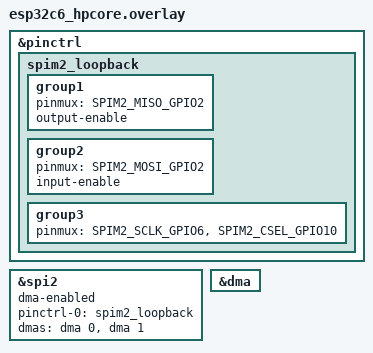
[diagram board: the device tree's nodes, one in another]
/*
 * Copyright (c) 2022 Kumar Gala <galak@kernel.org>
 *
 * SPDX-License-Identifier: Apache-2.0
 */

&pinctrl {
	spim2_loopback: spim2_loopback {
		group1 {
			pinmux = <SPIM2_MISO_GPIO2>;
			output-enable; /* Enable internal loopback */
		};

		group2 {
			pinmux = <SPIM2_MOSI_GPIO2>;
			input-enable; /* Enable internal loopback */
		};

		group3 {
			pinmux = <SPIM2_SCLK_GPIO6>,
				 <SPIM2_CSEL_GPIO10>;
		};
	};
};

spi_loopback: &spi2 {
	#address-cells = <1>;
	#size-cells = <0>;
	dma-enabled;
	pinctrl-0 = <&spim2_loopback>;
	pinctrl-names = "default";
	status = "okay";

	dmas = <&dma 0>, <&dma 1>;
	dma-names = "rx", "tx";
};

&dma {
	status = "okay";
};

#include "../spi-loopback.dtsi"
